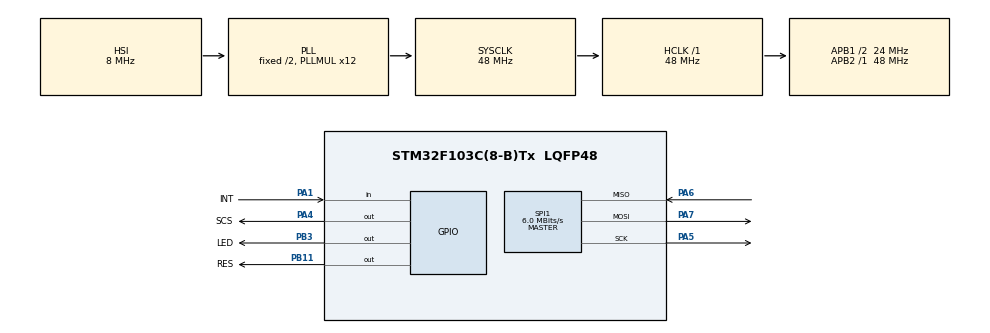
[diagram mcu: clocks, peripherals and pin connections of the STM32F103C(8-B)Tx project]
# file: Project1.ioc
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FREERTOS.Tasks01=LedBlinkTask,-2,64,StartLedBlinkTask;NetworkHandler,0,128,StartNetworkHandler
FREERTOS.configMINIMAL_STACK_SIZE=64
Mcu.Family=STM32F1
Mcu.Name=STM32F103C(8-B)Tx
Mcu.Package=LQFP48
NVIC.PriorityGroup=NVIC_PRIORITYGROUP_4
PA1.GPIO_Label=INT
PA1.GPIO_Mode=GPIO_MODE_INPUT
PA1.GPIO_PuPd=GPIO_NOPULL
PA1.Signal=GPIO_Input
PA13.Mode=Serial_Wire
PA13.Signal=SYS_JTMS-SWDIO
PA14.Mode=Serial_Wire
PA14.Signal=SYS_JTCK-SWCLK
PA4.GPIO_Label=SCS
PA4.GPIO_ModeDefaultOutputPP=GPIO_MODE_OUTPUT_PP
PA4.GPIO_Speed=GPIO_SPEED_LOW
PA4.Signal=GPIO_Output
PA5.Mode=Full_Duplex_Master
PA5.Signal=SPI1_SCK
PA6.Mode=Full_Duplex_Master
PA6.Signal=SPI1_MISO
PA7.Mode=Full_Duplex_Master
PA7.Signal=SPI1_MOSI
PB11.GPIO_Label=RES
PB11.GPIO_ModeDefaultOutputPP=GPIO_MODE_OUTPUT_PP
PB11.GPIO_Speed=GPIO_SPEED_LOW
PB11.Signal=GPIO_Output
PB3.GPIO_Label=LED
PB3.GPIO_ModeDefaultOutputPP=GPIO_MODE_OUTPUT_PP
PB3.GPIO_Speed=GPIO_SPEED_LOW
PB3.Signal=GPIO_Output
ProjectManager.TargetToolchain=EWARM
RCC.AHBFreq_Value=48000000
RCC.APB1CLKDivider=RCC_HCLK_DIV2
RCC.APB1Freq_Value=24000000
RCC.APB1TimCLKDivider=1
RCC.APB1TimFreq_Value=24000000
RCC.APB2Freq_Value=48000000
RCC.APB2TimFreq_Value=48000000
RCC.HCLKFreq_Value=48000000
RCC.PLLMUL=RCC_PLL_MUL12
RCC.SYSCLKFreq_VALUE=48000000
RCC.SYSCLKSource=RCC_SYSCLKSOURCE_PLLCLK
RCC.USBFreq_Value=48000000
SPI1.BaudRatePrescaler=SPI_BAUDRATEPRESCALER_8
SPI1.CalculateBaudRate=6.0 MBits/s
SPI1.Mode=SPI_MODE_MASTER
VP_FREERTOS_VS_ENABLE.Mode=Enabled

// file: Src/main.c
/**
  ******************************************************************************
  * File Name          : main.c
  * Description        : Main program body
  ******************************************************************************
  *
  * COPYRIGHT(c) 2016 STMicroelectronics
  *
  * Redistribution and use in source and binary forms, with or without modification,
  * are permitted provided that the following conditions are met:
  *   1. Redistributions of source code must retain the above copyright notice,
  *      this list of conditions and the following disclaimer.
  *   2. Redistributions in binary form must reproduce the above copyright notice,
  *      this list of conditions and the following disclaimer in the documentation
  *      and/or other materials provided with the distribution.
  *   3. Neither the name of STMicroelectronics nor the names of its contributors
  *      may be used to endorse or promote products derived from this software
  *      without specific prior written permission.
  *
  * THIS SOFTWARE IS PROVIDED BY THE COPYRIGHT HOLDERS AND CONTRIBUTORS "AS IS"
  * AND ANY EXPRESS OR IMPLIED WARRANTIES, INCLUDING, BUT NOT LIMITED TO, THE
  * IMPLIED WARRANTIES OF MERCHANTABILITY AND FITNESS FOR A PARTICULAR PURPOSE ARE
  * DISCLAIMED. IN NO EVENT SHALL THE COPYRIGHT HOLDER OR CONTRIBUTORS BE LIABLE
  * FOR ANY DIRECT, INDIRECT, INCIDENTAL, SPECIAL, EXEMPLARY, OR CONSEQUENTIAL
  * DAMAGES (INCLUDING, BUT NOT LIMITED TO, PROCUREMENT OF SUBSTITUTE GOODS OR
  * SERVICES; LOSS OF USE, DATA, OR PROFITS; OR BUSINESS INTERRUPTION) HOWEVER
  * CAUSED AND ON ANY THEORY OF LIABILITY, WHETHER IN CONTRACT, STRICT LIABILITY,
  * OR TORT (INCLUDING NEGLIGENCE OR OTHERWISE) ARISING IN ANY WAY OUT OF THE USE
  * OF THIS SOFTWARE, EVEN IF ADVISED OF THE POSSIBILITY OF SUCH DAMAGE.
  *
  ******************************************************************************
  */

#include "stm32f1xx_hal.h"
#include "cmsis_os.h"
//configuration - stm32f1xx_hal_conf.h

/* USER CODE BEGIN Includes */
//STM32F103C8T6 - 64 kb flash, 20 kb ram
#include "network_low.h"
#include "web_server.h"
#include "power_counting.h"
#include "generate_json.h"
#include "rtc_functions.h"
#include "dwt_timer.h"
#include "dht11.h"
#include "stdio.h"
/* USER CODE END Includes */

SPI_HandleTypeDef hspi1;
UART_HandleTypeDef huart1;
IWDG_HandleTypeDef hiwdg;

osThreadId LedBlinkTaskHandle;
osThreadId NetworkHandlerHandle;
osThreadId WebServerTaskHandle;
osThreadId RTCUpdateTaskHandle;
osThreadId PowerCountTaskHandle;
osThreadId DHT11TaskHandle;

/* USER CODE BEGIN PV */
extern TypeEthState ethernet_state;
/* USER CODE END PV */

void SystemClock_Config(void);
static void MX_GPIO_Init(void);
static void MX_SPI1_Init(void);
static void MX_IWDG_Init(void);
//static void MX_USART1_UART_Init(void);

void StartLedBlinkTask(void const * argument);
void StartNetworkHandler(void const * argument);
void StartWebServerHandler(void const * argument);
void StartRTCUpdateHandler(void const * argument);
void StartPowerCountHandler(void const * argument);
void StartDHT11Handler(void const * argument);

int main(void)
{

  /* MCU Configuration----------------------------------------------------------*/

  /* Reset of all peripherals, Initializes the Flash interface and the Systick. */
  HAL_Init();

  /* Configure the system clock */
  SystemClock_Config();

  /* Initialize all configured peripherals */
  MX_GPIO_Init();
  MX_SPI1_Init();
  MX_IWDG_Init();
  //MX_USART1_UART_Init();

  /* USER CODE BEGIN 2 */
#ifdef DEBUG
  printf("START APP\r\n");
#endif

  generate_json_data1();
  w5500_reset();
  DWT_Init();

  __HAL_SPI_ENABLE(&hspi1);

  rtc_init();
  power_counting_init();
  config_w5500_stack();
  init2_w5500();
  //init_sntp_module();

  /* USER CODE END 2 */

  /* Create the thread(s) */
  /* definition and creation of LedBlinkTask */
  osThreadDef(LedBlinkTask, StartLedBlinkTask, osPriorityNormal, 0, 64);
  LedBlinkTaskHandle = osThreadCreate(osThread(LedBlinkTask), NULL);

  /* definition and creation of NetworkHandler */
  osThreadDef(NetworkHandler, StartNetworkHandler, osPriorityNormal, 0, 128);
  NetworkHandlerHandle = osThreadCreate(osThread(NetworkHandler), NULL);

  /* definition and creation of NetworkHandler */
  osThreadDef(PowerCountHandler, StartPowerCountHandler, osPriorityNormal, 0, 64);
  PowerCountTaskHandle = osThreadCreate(osThread(PowerCountHandler), NULL);

  /* USER CODE BEGIN RTOS_THREADS */
  osThreadDef(WebServerTask, StartWebServerHandler, osPriorityLow, 0, 256);
  WebServerTaskHandle = osThreadCreate(osThread(WebServerTask), NULL);

  osThreadDef(RTCUpdateTask, StartRTCUpdateHandler, osPriorityLow, 0, 128);
  RTCUpdateTaskHandle = osThreadCreate(osThread(RTCUpdateTask), NULL);

  osThreadDef(DHT11Task, StartDHT11Handler, osPriorityLow, 0, 128);
  DHT11TaskHandle = osThreadCreate(osThread(DHT11Task), NULL);
  /* USER CODE END RTOS_THREADS */

  /* Start scheduler */
  osKernelStart();

  /* We should never get here as control is now taken by the scheduler */

  /* Infinite loop */
  while (1)
  {

  }
}

/** System Clock Configuration
*/
void SystemClock_Config(void)
{

  RCC_OscInitTypeDef RCC_OscInitStruct;
  RCC_ClkInitTypeDef RCC_ClkInitStruct;

  RCC_OscInitStruct.OscillatorType = RCC_OSCILLATORTYPE_HSI;
  RCC_OscInitStruct.HSIState = RCC_HSI_ON;
  RCC_OscInitStruct.HSICalibrationValue = 16;
  RCC_OscInitStruct.PLL.PLLState = RCC_PLL_ON;
  RCC_OscInitStruct.PLL.PLLSource = RCC_PLLSOURCE_HSI_DIV2;
  RCC_OscInitStruct.PLL.PLLMUL = RCC_PLL_MUL12;
  HAL_RCC_OscConfig(&RCC_OscInitStruct);

  RCC_ClkInitStruct.ClockType = RCC_CLOCKTYPE_SYSCLK|RCC_CLOCKTYPE_PCLK1;
  RCC_ClkInitStruct.SYSCLKSource = RCC_SYSCLKSOURCE_PLLCLK;
  RCC_ClkInitStruct.AHBCLKDivider = RCC_SYSCLK_DIV1;
  RCC_ClkInitStruct.APB1CLKDivider = RCC_HCLK_DIV2;
  RCC_ClkInitStruct.APB2CLKDivider = RCC_HCLK_DIV1;
  HAL_RCC_ClockConfig(&RCC_ClkInitStruct, FLASH_LATENCY_1);

  HAL_SYSTICK_Config(HAL_RCC_GetHCLKFreq()/1000);

  HAL_SYSTICK_CLKSourceConfig(SYSTICK_CLKSOURCE_HCLK);

}

/* SPI1 init function */
void MX_SPI1_Init(void)
{

  hspi1.Instance = SPI1;
  hspi1.Init.Mode = SPI_MODE_MASTER;
  hspi1.Init.Direction = SPI_DIRECTION_2LINES;
  hspi1.Init.DataSize = SPI_DATASIZE_8BIT;
  hspi1.Init.CLKPolarity = SPI_POLARITY_LOW;
  hspi1.Init.CLKPhase = SPI_PHASE_1EDGE;
  hspi1.Init.NSS = SPI_NSS_SOFT;
  hspi1.Init.BaudRatePrescaler = SPI_BAUDRATEPRESCALER_16;
  hspi1.Init.FirstBit = SPI_FIRSTBIT_MSB;
  hspi1.Init.TIMode = SPI_TIMODE_DISABLED;
  hspi1.Init.CRCCalculation = SPI_CRCCALCULATION_DISABLED;
  hspi1.Init.CRCPolynomial = 10;
  HAL_SPI_Init(&hspi1);
}

/** Configure pins as
        * Analog
        * Input
        * Output
        * EVENT_OUT
        * EXTI
*/
void MX_GPIO_Init(void)
{

  GPIO_InitTypeDef GPIO_InitStruct;

  /* GPIO Ports Clock Enable */
  __GPIOA_CLK_ENABLE();
  __GPIOB_CLK_ENABLE();

  /*Configure GPIO pin : PA1 */
  GPIO_InitStruct.Pin = GPIO_PIN_1;
  GPIO_InitStruct.Mode = GPIO_MODE_INPUT;
  GPIO_InitStruct.Pull = GPIO_NOPULL;
  HAL_GPIO_Init(GPIOA, &GPIO_InitStruct);

  /*Configure GPIO pin : PA4 */
  GPIO_InitStruct.Pin = GPIO_PIN_4;
  GPIO_InitStruct.Mode = GPIO_MODE_OUTPUT_PP;
  GPIO_InitStruct.Speed = GPIO_SPEED_HIGH;
  HAL_GPIO_Init(GPIOA, &GPIO_InitStruct);

  /*Configure GPIO pins : PB11 PB3 */
  GPIO_InitStruct.Pin = GPIO_PIN_11 | GPIO_PIN_3;
  GPIO_InitStruct.Mode = GPIO_MODE_OUTPUT_PP;
  GPIO_InitStruct.Speed = GPIO_SPEED_LOW;
  HAL_GPIO_Init(GPIOB, &GPIO_InitStruct);

  /*Configure GPIO pin : PB7 */
  GPIO_InitStruct.Pin = GPIO_PIN_7;
  GPIO_InitStruct.Mode = GPIO_MODE_IT_RISING;
  GPIO_InitStruct.Pull = GPIO_PULLDOWN;
  HAL_GPIO_Init(GPIOB, &GPIO_InitStruct);
}

/* IWDG init function */
static void MX_IWDG_Init(void)
{

  hiwdg.Instance = IWDG;
  hiwdg.Init.Prescaler = IWDG_PRESCALER_16;
  hiwdg.Init.Reload = 4095;
  if (HAL_IWDG_Init(&hiwdg) != HAL_OK)
  {
  }
  HAL_IWDG_Start(&hiwdg);

}

/* StartLedBlinkTask function */
void StartLedBlinkTask(void const * argument)
{

  /* USER CODE BEGIN 5 */
  /* Infinite loop */
  for(;;)
  {
    HAL_GPIO_TogglePin(GPIOB, GPIO_PIN_3);
    osDelay(100);
  }
  /* USER CODE END 5 */
}

/* StartNetworkHandler function */
void StartNetworkHandler(void const * argument)
{
  /* USER CODE BEGIN StartNetworkHandler */
  /* Infinite loop */
  for(;;)
  {
    DHCP_routine();
    if (ethernet_state == ETH_STATE_GOT_IP)
    {
      network_dns_handling();
      osDelay(1000);
    }
    else
    {
      osDelay(50);//dhcp needs small period?
    }
  }
  /* USER CODE END StartNetworkHandler */
}

void StartWebServerHandler(void const * argument)
{
  for(;;)
  {
    osDelay(100);
    web_server_handler();
  }
}

void StartRTCUpdateHandler(void const * argument)
{
  for(;;)
  {
    osDelay(300);
    rtc_update_handler();
  }
}

void StartDHT11Handler(void const * argument)
{
  for(;;)
  {
    osDelay(5000);
    DHT11_handler();
  }
}

void StartPowerCountHandler(void const * argument)
{
  for(;;)
  {
    osDelay(100);
    power_counting_handler();
    HAL_IWDG_Refresh(&hiwdg);
  }
}

/************************ (C) COPYRIGHT STMicroelectronics *****END OF FILE****/
